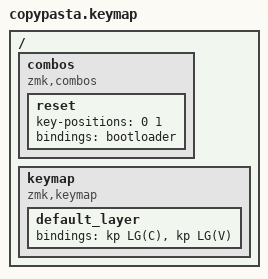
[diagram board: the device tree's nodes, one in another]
#include <behaviors.dtsi>
#include <dt-bindings/zmk/keys.h>
#include <dt-bindings/zmk/bt.h>


/ {

    combos {
        compatible = "zmk,combos";
        reset { key-positions = <0 1>; bindings = <&bootloader>; };

    };

    keymap {
        compatible = "zmk,keymap";

        default_layer {

            bindings = <
            &kp LG(C) &kp LG(V)
            >;
        };
    };
};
